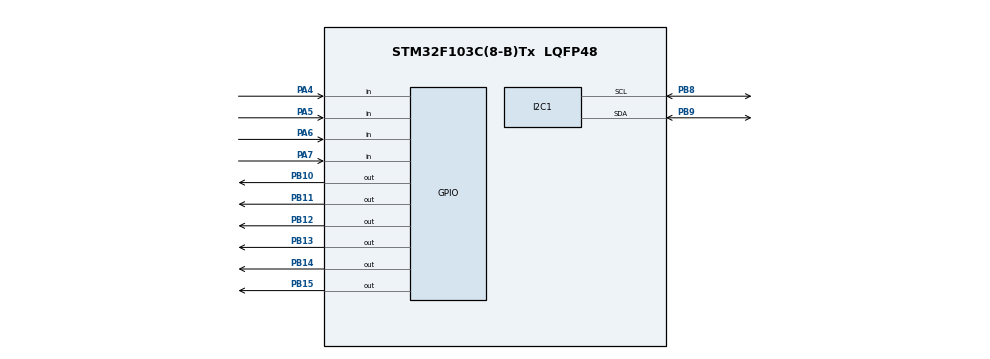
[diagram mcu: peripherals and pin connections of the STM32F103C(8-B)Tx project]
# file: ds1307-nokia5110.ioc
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Mcu.Family=STM32F1
Mcu.Name=STM32F103C(8-B)Tx
Mcu.Package=LQFP48
NVIC.PriorityGroup=NVIC_PRIORITYGROUP_4
PA13.Mode=Serial_Wire
PA13.Signal=SYS_JTMS-SWDIO
PA14.Mode=Serial_Wire
PA14.Signal=SYS_JTCK-SWCLK
PA4.Signal=GPIO_Input
PA5.Signal=GPIO_Input
PA6.Signal=GPIO_Input
PA7.Signal=GPIO_Input
PB10.Signal=GPIO_Output
PB11.Signal=GPIO_Output
PB12.Signal=GPIO_Output
PB13.Signal=GPIO_Output
PB14.Signal=GPIO_Output
PB15.Signal=GPIO_Output
PB8.Mode=I2C
PB8.Signal=I2C1_SCL
PB9.Mode=I2C
PB9.Signal=I2C1_SDA
PD0-OSC_IN.Mode=HSE-External-Oscillator
PD0-OSC_IN.Signal=RCC_OSC_IN
PD1-OSC_OUT.Mode=HSE-External-Oscillator
PD1-OSC_OUT.Signal=RCC_OSC_OUT
ProjectManager.HeapSize=0x200
ProjectManager.StackSize=0x400
ProjectManager.TargetToolchain=MDK-ARM V5
RCC.APB1Freq_Value=8000000
RCC.APB2Freq_Value=8000000
board=ds1307-nokia5110

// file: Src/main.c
/**
  ******************************************************************************
  * @file           : main.c
  * @brief          : Main program body
  ******************************************************************************
  ** This notice applies to any and all portions of this file
  * that are not between comment pairs USER CODE BEGIN and
  * USER CODE END. Other portions of this file, whether
  * inserted by the user or by software development tools
  * are owned by their respective copyright owners.
  *
  * COPYRIGHT(c) 2018 STMicroelectronics
  *
  * Redistribution and use in source and binary forms, with or without modification,
  * are permitted provided that the following conditions are met:
  *   1. Redistributions of source code must retain the above copyright notice,
  *      this list of conditions and the following disclaimer.
  *   2. Redistributions in binary form must reproduce the above copyright notice,
  *      this list of conditions and the following disclaimer in the documentation
  *      and/or other materials provided with the distribution.
  *   3. Neither the name of STMicroelectronics nor the names of its contributors
  *      may be used to endorse or promote products derived from this software
  *      without specific prior written permission.
  *
  * THIS SOFTWARE IS PROVIDED BY THE COPYRIGHT HOLDERS AND CONTRIBUTORS "AS IS"
  * AND ANY EXPRESS OR IMPLIED WARRANTIES, INCLUDING, BUT NOT LIMITED TO, THE
  * IMPLIED WARRANTIES OF MERCHANTABILITY AND FITNESS FOR A PARTICULAR PURPOSE ARE
  * DISCLAIMED. IN NO EVENT SHALL THE COPYRIGHT HOLDER OR CONTRIBUTORS BE LIABLE
  * FOR ANY DIRECT, INDIRECT, INCIDENTAL, SPECIAL, EXEMPLARY, OR CONSEQUENTIAL
  * DAMAGES (INCLUDING, BUT NOT LIMITED TO, PROCUREMENT OF SUBSTITUTE GOODS OR
  * SERVICES; LOSS OF USE, DATA, OR PROFITS; OR BUSINESS INTERRUPTION) HOWEVER
  * CAUSED AND ON ANY THEORY OF LIABILITY, WHETHER IN CONTRACT, STRICT LIABILITY,
  * OR TORT (INCLUDING NEGLIGENCE OR OTHERWISE) ARISING IN ANY WAY OUT OF THE USE
  * OF THIS SOFTWARE, EVEN IF ADVISED OF THE POSSIBILITY OF SUCH DAMAGE.
  *
  ******************************************************************************
  */
#include "main.h"
#include "stm32f1xx_hal.h"

/* USER CODE BEGIN Includes */
//Hung
#include "nokia_5110.h"
#include "hinh_anh.h"

#include "stdio.h" 			// Thu vien chua ham sprintf
#include "string.h"			// Thu vien chua ham strlen()

// doc ds1307
#include "ds1307.h"

/* USER CODE END Includes */

I2C_HandleTypeDef hi2c1;

/* USER CODE BEGIN PV */
/* Private variables ---------------------------------------------------------*/

//Hung
char lcdBuff[64];
char hh, mm, ss;
char dd, DD, MM, YY;
int doDaiChuoi;

/* USER CODE END PV */

void SystemClock_Config(void);
static void MX_GPIO_Init(void);
static void MX_I2C1_Init(void);

/* USER CODE BEGIN PFP */
/* Private function prototypes -----------------------------------------------*/

/* USER CODE END PFP */

int main(void)
{

  /* MCU Configuration----------------------------------------------------------*/

  /* Reset of all peripherals, Initializes the Flash interface and the Systick. */
  HAL_Init();

  /* Configure the system clock */
  SystemClock_Config();

  /* Initialize all configured peripherals */
  MX_GPIO_Init();
  MX_I2C1_Init();
  /* USER CODE BEGIN 2 */

	//Hung
	LCDInit(0x30, 0, 1);
	HAL_Delay(10);
	HAL_GPIO_WritePin(GPIOB, GPIO_PIN_15, GPIO_PIN_SET);
	LCDClear();
	//Ds1307
	// Initialize DS1307
  //rtcWriteTime(21,13, 50); //Thiet lap thoi gian
	//rtcWriteDate(5, 17, 8, 17); //Thiet lap ngay thang

  /* USER CODE END 2 */

  /* Infinite loop */
  while (1)
  {

		//Test LCD Nokia 5110
    gotoXY(0,0);
//		sprintf(lcdBuff, "Chao Hung");
//		doDaiChuoi = strlen(lcdBuff);   // Lay do dai cua choi trong mang buffer
//		LCDString(lcdBuff);

//		//Doc DS1307
		rtcReadTime(&hh, &mm, &ss);
//		sprintf(&lcdBuff[0], "%0.2d:%0.2d:%0.2d", hh, mm, ss);
//		gotoXY(0,1);
//		LCDString(&lcdBuff[0]);
//
		rtcReadDate(&dd, &DD, &MM, &YY);
//		sprintf(&lcdBuff[0], "%0.2d-%0.2d/%0.2d/20%0.2d", dd, DD, MM, YY);
//		gotoXY(0,2);
//		LCDString(&lcdBuff[0]);

		gotoXY(0, 1);
		sprintf(&lcdBuff[0], (DD <= 9) ? "0%d" : "%d", DD);
		LCDString(&lcdBuff[0]);
		LCDString("/");
		sprintf(&lcdBuff[0], (MM <= 9) ? "0%d" : "%d", MM);
		LCDString(&lcdBuff[0]);
		LCDString("/");
		sprintf(&lcdBuff[0], "20%d", YY);
		LCDString(&lcdBuff[0]);

		gotoXY(0, 2);
		sprintf(&lcdBuff[0], (hh <= 9) ? "0%d" : "%d", hh);
		LCDString(&lcdBuff[0]);
		LCDString(":");
		sprintf(&lcdBuff[0], (mm <= 9) ? "0%d" : "%d", mm);
		LCDString(&lcdBuff[0]);
		LCDString(":");
		sprintf(&lcdBuff[0], (ss <= 9) ? "0%d" : "%d", ss);
		LCDString(&lcdBuff[0]);

		HAL_Delay(300);

  }

}

//Hung
void HAL_GPIO_EXTI_Callback(uint16_t GPIO_Pin){
	if(GPIO_Pin==GPIO_PIN_6){

	}
}
void SystemClock_Config(void)
{

  RCC_OscInitTypeDef RCC_OscInitStruct;
  RCC_ClkInitTypeDef RCC_ClkInitStruct;

    /**Initializes the CPU, AHB and APB busses clocks
    */
  RCC_OscInitStruct.OscillatorType = RCC_OSCILLATORTYPE_HSI;
  RCC_OscInitStruct.HSIState = RCC_HSI_ON;
  RCC_OscInitStruct.HSICalibrationValue = 16;
  RCC_OscInitStruct.PLL.PLLState = RCC_PLL_NONE;
  if (HAL_RCC_OscConfig(&RCC_OscInitStruct) != HAL_OK)
  {
    _Error_Handler(__FILE__, __LINE__);
  }

    /**Initializes the CPU, AHB and APB busses clocks
    */
  RCC_ClkInitStruct.ClockType = RCC_CLOCKTYPE_HCLK|RCC_CLOCKTYPE_SYSCLK
                              |RCC_CLOCKTYPE_PCLK1|RCC_CLOCKTYPE_PCLK2;
  RCC_ClkInitStruct.SYSCLKSource = RCC_SYSCLKSOURCE_HSI;
  RCC_ClkInitStruct.AHBCLKDivider = RCC_SYSCLK_DIV1;
  RCC_ClkInitStruct.APB1CLKDivider = RCC_HCLK_DIV1;
  RCC_ClkInitStruct.APB2CLKDivider = RCC_HCLK_DIV1;

  if (HAL_RCC_ClockConfig(&RCC_ClkInitStruct, FLASH_LATENCY_0) != HAL_OK)
  {
    _Error_Handler(__FILE__, __LINE__);
  }

    /**Configure the Systick interrupt time
    */
  HAL_SYSTICK_Config(HAL_RCC_GetHCLKFreq()/1000);

    /**Configure the Systick
    */
  HAL_SYSTICK_CLKSourceConfig(SYSTICK_CLKSOURCE_HCLK);

  /* SysTick_IRQn interrupt configuration */
  HAL_NVIC_SetPriority(SysTick_IRQn, 0, 0);
}

/* I2C1 init function */
static void MX_I2C1_Init(void)
{

  hi2c1.Instance = I2C1;
  hi2c1.Init.ClockSpeed = 100000;
  hi2c1.Init.DutyCycle = I2C_DUTYCYCLE_2;
  hi2c1.Init.OwnAddress1 = 0;
  hi2c1.Init.AddressingMode = I2C_ADDRESSINGMODE_7BIT;
  hi2c1.Init.DualAddressMode = I2C_DUALADDRESS_DISABLE;
  hi2c1.Init.OwnAddress2 = 0;
  hi2c1.Init.GeneralCallMode = I2C_GENERALCALL_DISABLE;
  hi2c1.Init.NoStretchMode = I2C_NOSTRETCH_DISABLE;
  if (HAL_I2C_Init(&hi2c1) != HAL_OK)
  {
    _Error_Handler(__FILE__, __LINE__);
  }

}

/** Configure pins as
        * Analog
        * Input
        * Output
        * EVENT_OUT
        * EXTI
*/
static void MX_GPIO_Init(void)
{

  GPIO_InitTypeDef GPIO_InitStruct;

  /* GPIO Ports Clock Enable */
  __HAL_RCC_GPIOD_CLK_ENABLE();
  __HAL_RCC_GPIOA_CLK_ENABLE();
  __HAL_RCC_GPIOB_CLK_ENABLE();

  /*Configure GPIO pin Output Level */
  HAL_GPIO_WritePin(GPIOB, GPIO_PIN_10|GPIO_PIN_11|GPIO_PIN_12|GPIO_PIN_13
                          |GPIO_PIN_14|GPIO_PIN_15, GPIO_PIN_RESET);

  /*Configure GPIO pins : PA4 PA5 PA6 PA7 */
  GPIO_InitStruct.Pin = GPIO_PIN_4|GPIO_PIN_5|GPIO_PIN_6|GPIO_PIN_7;
  GPIO_InitStruct.Mode = GPIO_MODE_INPUT;
  GPIO_InitStruct.Pull = GPIO_NOPULL;
  HAL_GPIO_Init(GPIOA, &GPIO_InitStruct);

  /*Configure GPIO pins : PB10 PB11 PB12 PB13
                           PB14 PB15 */
  GPIO_InitStruct.Pin = GPIO_PIN_10|GPIO_PIN_11|GPIO_PIN_12|GPIO_PIN_13
                          |GPIO_PIN_14|GPIO_PIN_15;
  GPIO_InitStruct.Mode = GPIO_MODE_OUTPUT_PP;
  GPIO_InitStruct.Speed = GPIO_SPEED_FREQ_LOW;
  HAL_GPIO_Init(GPIOB, &GPIO_InitStruct);

}

void _Error_Handler(char *file, int line)
{
  while(1)
  {
  }
}

/************************ (C) COPYRIGHT STMicroelectronics *****END OF FILE****/
